# GD32E511_512 register map
File version: 1.0
CPU: CM33 r0p4, little endian, MPU, FPU, 4 interrupt priority bits
Registers are 32-bit, read-write, reset 0x0 unless marked. A register's access mark holds for its fields unless they carry their own. Offsets are from the block's base; [hi:lo] are bit positions; 'fields as' and 'values as' point back to an identical list.

## UART3 — Universal asynchronous receiver transmitter
Base 0x40004400
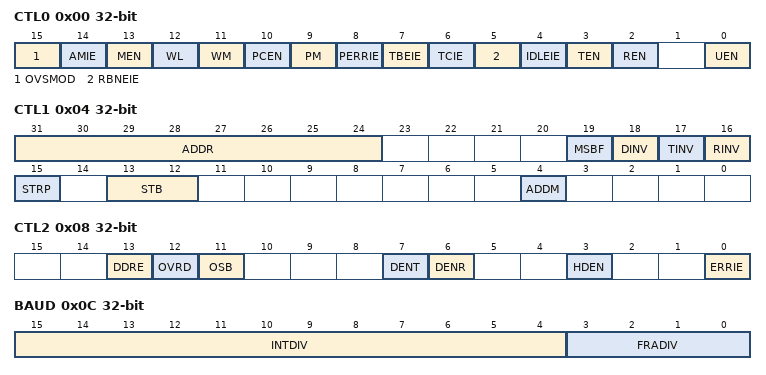
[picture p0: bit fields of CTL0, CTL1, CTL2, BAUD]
0x00 CTL0 — Control register 0
  [15] OVSMOD — Oversample mode
  [14] AMIE — ADDR match interrupt enable.
  [13] MEN — Mute mode enable.
  [12] WL — Word length
  [11] WM — Wakeup method in mute mode.
  [10] PCEN — Parity control enable.
  [9] PM — Parity mode
  [8] PERRIE — Parity error interrupt enable.
  [7] TBEIE — Transmitter register empty interrupt enable.
  [6] TCIE — Transmission complete interrupt enable.
  [5] RBNEIE — Read data buffer not empty interrupt and overrun error interrupt enable.
  [4] IDLEIE — IDLE line detected interrupt enable.
  [3] TEN — Transmitter enable.
  [2] REN — Receiver enable.
  [0] UEN — USART enable
0x04 CTL1 — Control register 1
  [31:24] ADDR — Address of the USART terminal.
  [19] MSBF — Most significant bit first.
  [18] DINV — Data bit level inversion.
  [17] TINV — TX pin level inversion.
  [16] RINV — RX pin level inversion.
  [15] STRP — Swap TX/RX pins.
  [13:12] STB — STOP bits length.
  [4] ADDM — Address detection mode.
0x08 CTL2 — Control register 2
  [13] DDRE — Mask DMA request on reception error
  [12] OVRD — Overrun disable
  [11] OSB — One sample bit method.
  [7] DENT — DMA enable for transmission.
  [6] DENR — DMA enable for reception.
  [3] HDEN — Half-duplex enable.
  [0] ERRIE — Error interrupt enable.
0x0C BAUD — Baud rate generator register
  [15:4] INTDIV — Integer of baud-rate divider.
  [3:0] FRADIV — Fraction of baud-rate divider.
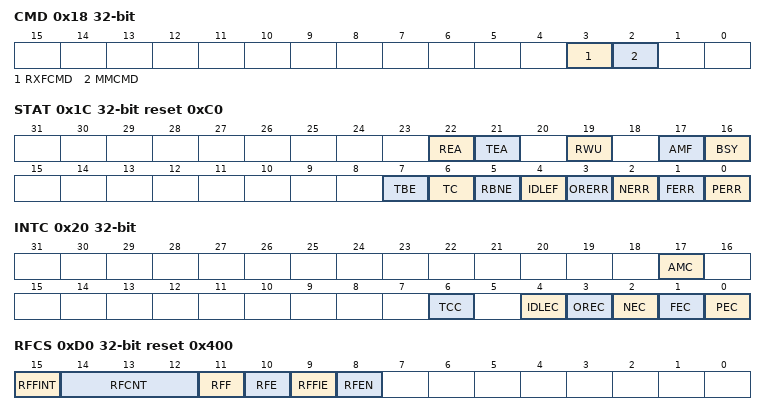
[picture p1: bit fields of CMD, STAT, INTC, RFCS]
0x18 CMD wo — Command register
  [3] RXFCMD — Receive data flush command.
  [2] MMCMD — Mute mode command.
0x1C STAT ro reset 0xC0 — Status register
  [22] REA — Receive enable acknowledge flag.
  [21] TEA — Transmit enable acknowledge flag.
  [19] RWU — Receiver wakeup from mute mode
  [17] AMF — ADDR match flag
  [16] BSY — Busy flag
  [7] TBE — Transmit data register empty.
  [6] TC — Transmission completed
  [5] RBNE — Read data buffer not empty.
  [4] IDLEF — IDLE line detected flag.
  [3] ORERR — Overrun error
  [2] NERR — Noise error flag
  [1] FERR — Frame error flag
  [0] PERR — Parity error flag.
0x20 INTC wo — Interrupt status clear register
  [17] AMC — ADDR match clear.
  [6] TCC — Transmission complete clear.
  [4] IDLEC — Idle line detected clear.
  [3] OREC — Overrun error clear.
  [2] NEC — Noise detected clear.
  [1] FEC — Frame error flag clear.
  [0] PEC — Parity error clear.
0x24 RDATA ro — Receive data register
  [8:0] RDATA — Receive data value.
0x28 TDATA — Transmit data register
  [8:0] TDATA — Transmit data value
0xC0 CHC — USART coherence control register
  [8] EPERR — Early parity error flag. This flag will be set as soon as the parity bit has been detected, which is before RBNE flag. This flag is cleared by writing 0.
0xD0 RFCS access per field reset 0x400 — USART receive FIFO control and status register
  [15] RFFINT rw — Receive FIFO full interrupt flag. This flag is cleared by writing 0.
  [14:12] RFCNT ro — Receive FIFO counter number.
  [11] RFF ro — Receive FIFO full flag.
  [10] RFE ro — Receive FIFO empty flag.
  [9] RFFIE rw — Receive FIFO full interrupt enable.
  [8] RFEN rw — Receive FIFO enable.

## WWDGT — Window watchdog timer
Base 0x40002C00
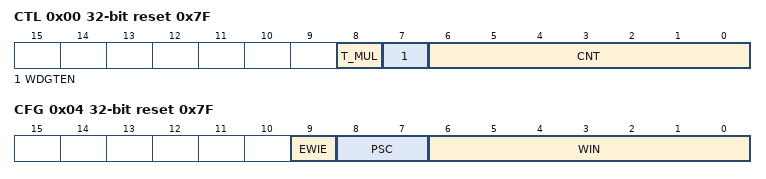
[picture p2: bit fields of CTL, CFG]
0x00 CTL reset 0x7F — Control register
  [8] T_MUL — Higher clock prescaler enable
  [7] WDGTEN — Activation bit
  [6:0] CNT — 7-bit counter
0x04 CFG reset 0x7F — Configuration register
  [9] EWIE — Early wakeup interrupt enables
  [8:7] PSC — Prescaler
  [6:0] WIN — 7-bit window value
0x08 STAT — Status register
  [0] EWIF — Early wakeup interrupt flag

## OPA — Operational amplifiers
Base 0x40007C00
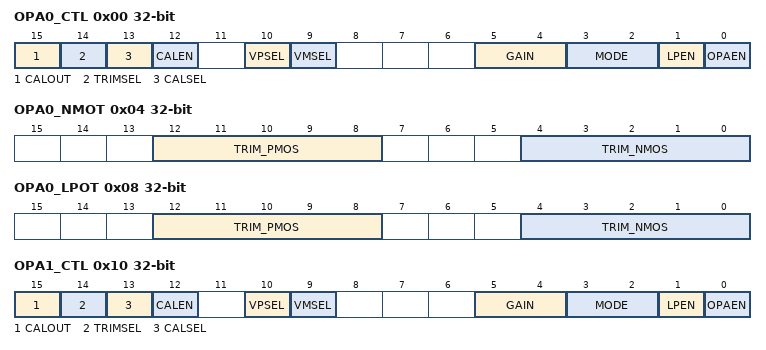
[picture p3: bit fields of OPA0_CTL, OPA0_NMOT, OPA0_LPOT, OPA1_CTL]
0x00 OPA0_CTL access per field — OPAx control regist 0
  [15] CALOUT ro — OPA calibration output
  [14] TRIMSEL rw — Select trim values for OPA offset.
  [13] CALSEL rw — Select calibration mode
  [12] CALEN rw — Enable calibration mode, all input will disconnect.
  [10] VPSEL rw — Non-inverted input (VINP) selection
  [9] VMSEL rw — Inverting input (VINM) selection.
  [5:4] GAIN rw — PGA gain value
  [3:2] MODE rw — OPA mode selection
  [1] LPEN rw — Low power mode enable
  [0] OPAEN rw — OPA enable
0x04 OPA0_NMOT — OPAx normal mode offset trim regist 0
  [12:8] TRIM_PMOS — Trim value for PMOS pairs
  [4:0] TRIM_NMOS — Trim value for NMOS pairs
0x08 OPA0_LPOT — OPAx low-power mode offset trim regist 0
  fields as OPA0_NMOT
0x10 OPA1_CTL access per field — OPAx control regist 1
  fields as OPA0_CTL
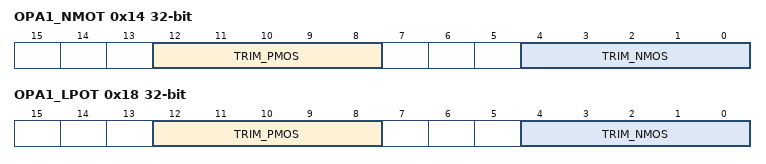
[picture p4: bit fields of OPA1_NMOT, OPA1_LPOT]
0x14 OPA1_NMOT — OPAx normal mode offset trim regist 1
  fields as OPA0_NMOT
0x18 OPA1_LPOT — OPAx low-power mode offset trim regist 1
  fields as OPA0_NMOT
